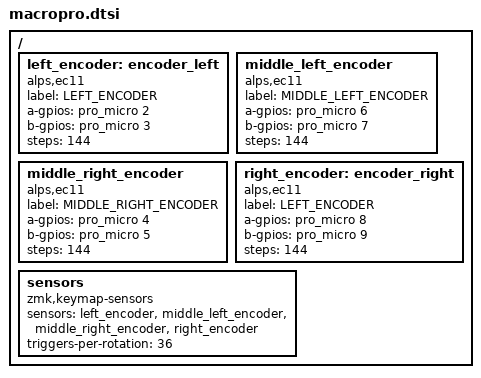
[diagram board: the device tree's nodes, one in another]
/ {
    left_encoder: encoder_left {
        compatible = "alps,ec11";
        label = "LEFT_ENCODER";
        a-gpios = <&pro_micro 2 (GPIO_ACTIVE_HIGH | GPIO_PULL_UP)>;
        b-gpios = <&pro_micro 3 (GPIO_ACTIVE_HIGH | GPIO_PULL_UP)>;
        steps = <144>;
        status = "okay";
    };

    middle_left_encoder: middle_left_encoder {
        compatible = "alps,ec11";
        label = "MIDDLE_LEFT_ENCODER";
        a-gpios = <&pro_micro 6 (GPIO_ACTIVE_HIGH | GPIO_PULL_UP)>;
        b-gpios = <&pro_micro 7 (GPIO_ACTIVE_HIGH | GPIO_PULL_UP)>;
        steps = <144>;
        status = "okay";
    };

    middle_right_encoder: middle_right_encoder {
        compatible = "alps,ec11";
        label = "MIDDLE_RIGHT_ENCODER";
        a-gpios = <&pro_micro 4 (GPIO_ACTIVE_HIGH | GPIO_PULL_UP)>;
        b-gpios = <&pro_micro 5 (GPIO_ACTIVE_HIGH | GPIO_PULL_UP)>;
        steps = <144>;
        status = "okay";
    };

    right_encoder: encoder_right {
        compatible = "alps,ec11";
        label = "LEFT_ENCODER";
        a-gpios = <&pro_micro 8 (GPIO_ACTIVE_HIGH | GPIO_PULL_UP)>;
        b-gpios = <&pro_micro 9 (GPIO_ACTIVE_HIGH | GPIO_PULL_UP)>;
        steps = <144>;
        status = "okay";
    };

    sensors {
        compatible = "zmk,keymap-sensors";
        sensors = <&left_encoder &middle_left_encoder &middle_right_encoder &right_encoder>;
        triggers-per-rotation = <36>;
    };
};
